# SAM9X75D1GN2 register map
Vendor: Microchip Technology; Series: SAM9X7; File version: 0
Registers are 32-bit, read-write, reset 0x0 unless marked. A register's access mark holds for its fields unless they carry their own. Offsets are from the block's base; [hi:lo] are bit positions; lines under a group give offsets from that group; {n}, {i} and the like mark numbered series.

## SMC — Static Memory Controller
Base 0xFFFFEA00
{0x0+0x10*i} SMC_CS_NUMBER[{i}] (i=0..2) group
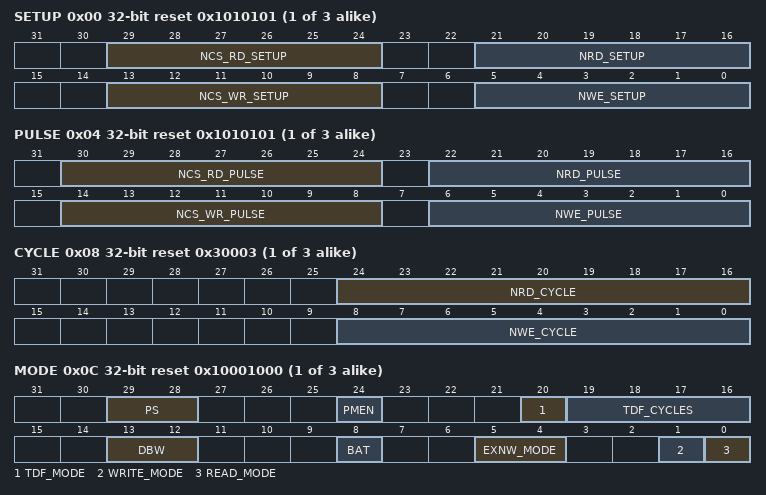
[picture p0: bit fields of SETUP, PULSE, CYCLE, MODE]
  0x00 SETUP reset 0x1010101 — SMC Setup Register
    [29:24] NCS_RD_SETUP — NCS Setup Length in READ Access
    [21:16] NRD_SETUP — NRD Setup Length
    [13:8] NCS_WR_SETUP — NCS Setup Length in WRITE Access
    [5:0] NWE_SETUP — NWE Setup Length
  0x04 PULSE reset 0x1010101 — SMC Pulse Register
    [30:24] NCS_RD_PULSE — NCS Pulse Length in READ Access
    [22:16] NRD_PULSE — NRD Pulse Length
    [14:8] NCS_WR_PULSE — NCS Pulse Length in WRITE Access
    [6:0] NWE_PULSE — NWE Pulse Length
  0x08 CYCLE reset 0x30003 — SMC Cycle Register
    [24:16] NRD_CYCLE — Total Read Cycle Length
    [8:0] NWE_CYCLE — Total Write Cycle Length
  0x0C MODE reset 0x10001000 — SMC Mode Register
    [29:28] PS — Page Size
      0=BYTE_4 (4-byte page); 1=BYTE_8 (8-byte page); 2=BYTE_16 (16-byte page); 3=BYTE_32 (32-byte page)
    [24] PMEN — Page Mode Enabled
      0=Standard read is applied; 1=Asynchronous burst read in Page mode is applied on the corresponding chip select
    [20] TDF_MODE — TDF Optimization
      0=TDF optimization disabled-The number of TDF wait states is inserted before the next access begins; 1=TDF optimization enabled-The number of TDF wait states is optimized using the setup period of the next read/write access
    [19:16] TDF_CYCLES — Data Float Time
    [13:12] DBW — Data Bus Width
      0=BIT_8 (8-bit bus); 1=BIT_16 (16-bit bus)
    [8] BAT — Byte Access Type
      0=BYTE_SELECT (Byte select access type: - Write operation is controlled using NCS, NWE, NBS0, NBS1 - Read operation is controlled using NCS, NRD, NBS0, NBS1); 1=BYTE_WRITE (Byte write access type: - Write operation is controlled using NCS, NWR0, NWR1 - Read operation is controlled using NCS and NRD)
    [5:4] EXNW_MODE — NWAIT Mode
      0=DISABLED (Disabled Mode-The NWAIT input signal is ignored on the corresponding Chip Select.); 2=FROZEN (Frozen Mode-If asserted, the NWAIT signal freezes the current read or write cycle. After deassertion, the read/write cycle is resumed from the point where it was stopped.); 3=READY (Ready Mode-The NWAIT signal indicates the availability of the external device at the end of the pulse of the controlling read or write signal, to complete the access. If high, the access normally completes. If low, the access is extended until NWAIT returns high.)
    [1] WRITE_MODE — Selection of the Control Signal for Write Operation
      0=NCS_CTRL (Write operation controlled by NCS signal-If TDF optimization is enabled (TDF_MODE = 1), TDF wait states will be inserted after the setup of NCS.); 1=NWE_CTRL (Write operation controlled by NWE signal-If TDF optimization is enabled (TDF_MODE = 1), TDF wait states will be inserted after the setup of NWE.)
    [0] READ_MODE — Selection of the Control Signal for Read Operation
      0=NCS_CTRL (Read operation controlled by NCS signal - If TDF cycles are programmed, the external bus is marked busy after the rising edge of NCS. - If TDF optimization is enabled (TDF_MODE = 1), TDF wait states are inserted after the setup of NCS.); 1=NRD_CTRL (Read operation controlled by NRD signal - If TDF cycles are programmed, the external bus is marked busy after the rising edge of NRD. - If TDF optimization is enabled (TDF_MODE = 1), TDF wait states are inserted after the setup of NRD.)
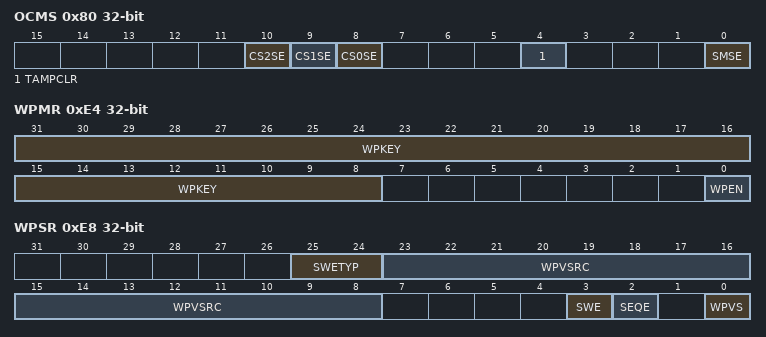
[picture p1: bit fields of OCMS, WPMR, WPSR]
0x80 OCMS — SMC Off-Chip Memory Scrambling Register
  [10] CS2SE — Chip Select (x = 0 to 2) Scrambling Enable
    0=Disables scrambling for CSx; 1=Enables scrambling for CSx
  [9] CS1SE — Chip Select (x = 0 to 2) Scrambling Enable
    0=Disables scrambling for CSx; 1=Enables scrambling for CSx
  [8] CS0SE — Chip Select (x = 0 to 2) Scrambling Enable
    0=Disables scrambling for CSx; 1=Enables scrambling for CSx
  [4] TAMPCLR — Tamper Clear Enable
    0=A tamper detection event has no effect on SMC scrambling keys; 1=A tamper detection event immediately clears SMC scrambling keys
  [0] SMSE — Static Memory Controller Scrambling Enable
    0=Disables scrambling for SMC access; 1=Enables scrambling for SMC access
0x84 KEY1 wo — SMC Off-Chip Memory Scrambling KEY1 Register
  [31:0] KEY1 — Off-Chip Memory Scrambling (OCMS) Key Part 1
0x88 KEY2 wo — SMC Off-Chip Memory Scrambling KEY2 Register
  [31:0] KEY2 — Off-Chip Memory Scrambling (OCMS) Key Part 2
0x90 SRIER — SMC Safety Report Interrupt Enable Register
  [0] SRIE — Safety Report Interrupt Enable
    0=Disables the SMC safety report interrupt from External Bus Interface; 1=Enables the SMC safety report interrupt from External Bus Interface
0xE4 WPMR — SMC Write Protection Mode Register
  [31:8] WPKEY — Write Protection Key
    0x534D43=PASSWD (Writing any other value in this field aborts the write operation of bit WPEN. Always reads as 0.)
  [0] WPEN — Write Protection Enable
    0=Disables write protection if WPKEY value corresponds to 0x534D43 ('SMC' in ASCII); 1=Enables write protection if WPKEY value corresponds to 0x534D43 ('SMC' in ASCII)
0xE8 WPSR ro — SMC Write Protection Status Register
  [25:24] SWETYP — Software Error Type (Cleared on read)
    0=READ_WO (A write-only register has been read.); 1=WRITE_RO (A write access has been performed on a read-only register.); 2=UNDEF_RW (Access to an undefined address.)
  [23:8] WPVSRC — Write Protection Violation Source
  [3] SWE — Software Control Error (Cleared on read)
    0=No software error has occurred since the last read of SMC_WPSR; 1=A software error has occurred since the last read of SMC_WPSR. The field SWETYP details the type of software error; the associated incorrect software access is reported in the field WPVSRC (if WPVS=0).
  [2] SEQE — Internal Sequencer Error (Cleared on read)
    0=No internal sequencer error has occurred since the last read of SMC_WPSR; 1=A internal sequencer error has occurred since the last read of SMC_WPSR. This flag can only be set under abnormal operating conditions.
  [0] WPVS — Write Protection Violation Status (Cleared on read)
    0=No write protection violation has occurred since the last read of the SMC_WPSR; 1=A write protection violation occurred since the last read of the SMC_WPSR. If this violation is an unauthorized attempt to write a protected register, the associated violation is reported into field WPVSRC.
